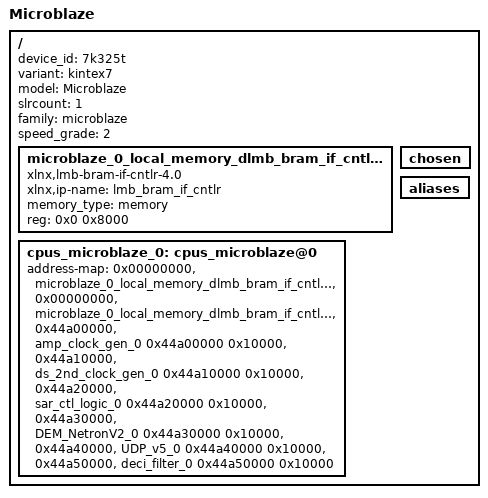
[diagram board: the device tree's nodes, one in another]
/dts-v1/;
#include "pl.dtsi"
/ {
	device_id = "7k325t";
	#address-cells = <1>;
	variant = "kintex7";
	model = "Microblaze";
	#size-cells = <1>;
	slrcount = <1>;
	family = "microblaze";
	speed_grade = "2";
	microblaze_0_local_memory_dlmb_bram_if_cntlr_memory: memory@0 {
		compatible = "xlnx,lmb-bram-if-cntlr-4.0";
		xlnx,ip-name = "lmb_bram_if_cntlr";
		device_type = "memory";
		memory_type = "memory";
		reg = <0x0 0x8000>;
	};
	chosen {
	};
	aliases {
	};
	cpus_microblaze_0: cpus_microblaze@0 {
		address-map = <0x00000000 &microblaze_0_local_memory_dlmb_bram_if_cntlr_memory 0x00000000 0x8000>, 
			      <0x00000000 &microblaze_0_local_memory_dlmb_bram_if_cntlr 0x00000000 0x8000>, 
			      <0x44a00000 &amp_clock_gen_0 0x44a00000 0x10000>, 
			      <0x44a10000 &ds_2nd_clock_gen_0 0x44a10000 0x10000>, 
			      <0x44a20000 &sar_ctl_logic_0 0x44a20000 0x10000>, 
			      <0x44a30000 &DEM_NetronV2_0 0x44a30000 0x10000>, 
			      <0x44a40000 &UDP_v5_0 0x44a40000 0x10000>, 
			      <0x44a50000 &deci_filter_0 0x44a50000 0x10000>;
		#ranges-address-cells = <0x1>;
		#ranges-size-cells = <0x1>;
	};
};
